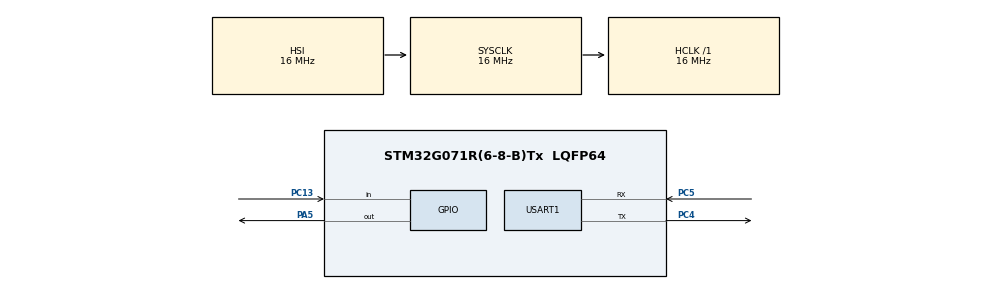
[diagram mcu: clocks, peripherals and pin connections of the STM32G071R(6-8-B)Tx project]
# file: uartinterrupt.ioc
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Mcu.Family=STM32G0
Mcu.Name=STM32G071R(6-8-B)Tx
Mcu.Package=LQFP64
NVIC.USART1_IRQn=true\:0\:0\:false\:false\:true\:true\:true
PA5.GPIO_Speed=GPIO_SPEED_FREQ_MEDIUM
PA5.Signal=GPIO_Output
PC13.Signal=GPIO_Input
PC4.Mode=Asynchronous
PC4.Signal=USART1_TX
PC5.Mode=Asynchronous
PC5.Signal=USART1_RX
ProjectManager.HeapSize=0x200
ProjectManager.StackSize=0x400
ProjectManager.TargetToolchain=MDK-ARM V5.27
RCC.AHBFreq_Value=16000000
RCC.CortexFreq_Value=16000000
RCC.EXTERNAL_CLOCK_VALUE=48000
RCC.HCLKFreq_Value=16000000
RCC.HSE_VALUE=8000000
RCC.HSI_VALUE=16000000
RCC.LSE_VALUE=32768
RCC.SYSCLKFreq_VALUE=16000000
RCC.VCOOutputFreq_Value=128000000
USART1.VirtualMode-Asynchronous=VM_ASYNC
VP_SYS_VS_DBSignals.Mode=DisableDeadBatterySignals
board=custom

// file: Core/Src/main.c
/* USER CODE BEGIN Header */
/**
  ******************************************************************************
  * @file           : main.c
  * @brief          : Main program body
  ******************************************************************************
  * @attention
  *
  * <h2><center>&copy; Copyright (c) 2021 STMicroelectronics.
  * All rights reserved.</center></h2>
  *
  * This software component is licensed by ST under BSD 3-Clause license,
  * the "License"; You may not use this file except in compliance with the
  * License. You may obtain a copy of the License at:
  *                        opensource.org/licenses/BSD-3-Clause
  *
  ******************************************************************************
  */
/* USER CODE END Header */
#include "main.h"
#define transmitter_board

UART_HandleTypeDef huart1;

/* USER CODE BEGIN PV */
__IO ITStatus uartready=RESET;
uint8_t TxMessage[1]={1};
uint8_t RxMessage[1];

uint8_t i=1;
/* USER CODE END PV */

void SystemClock_Config(void);
static void MX_GPIO_Init(void);
static void MX_USART1_UART_Init(void);

int main(void)
{

  /* MCU Configuration--------------------------------------------------------*/

  /* Reset of all peripherals, Initializes the Flash interface and the Systick. */
  HAL_Init();

  /* Configure the system clock */
  SystemClock_Config();

  /* Initialize all configured peripherals */
  MX_GPIO_Init();
  MX_USART1_UART_Init();
  /* USER CODE BEGIN 2 */

#ifdef transmitter_board
while(HAL_GPIO_ReadPin(GPIOC,GPIO_PIN_13)==1){

HAL_GPIO_TogglePin(GPIOA,GPIO_PIN_5);
	HAL_Delay(500);

}

if(HAL_UART_Transmit_IT(&huart1,(uint8_t *)TxMessage,1)!=HAL_OK)
	{
			Error_Handler();
	}
	while(uartready!=SET)
		{

		}

		uartready=RESET;
if(HAL_UART_Receive_IT(&huart1,(uint8_t *)RxMessage,1)!=HAL_OK)
	{
			Error_Handler();
	}

#else

   if(HAL_UART_Receive_IT(&huart1,(uint8_t *)RxMessage,1)!=HAL_OK){

			Error_Handler();

			}
	while(uartready!=SET)
		{

		}	uartready=RESET;
	if(HAL_UART_Transmit_IT(&huart1,(uint8_t *)TxMessage,1)!=HAL_OK)
			{

			Error_Handler();

			}

#endif

 while(uartready!=SET){

 }

 uartready=RESET;

 HAL_GPIO_WritePin(GPIOA,GPIO_PIN_5,GPIO_PIN_SET);
 while (1)
  {

			}
		/*TxMessage[0]=1;

	HAL_UART_Transmit_IT(&huart1,TxMessage,1);*/

    /* USER CODE END WHILE */

  }

void SystemClock_Config(void)
{
  RCC_OscInitTypeDef RCC_OscInitStruct = {0};
  RCC_ClkInitTypeDef RCC_ClkInitStruct = {0};
  RCC_PeriphCLKInitTypeDef PeriphClkInit = {0};

  /** Configure the main internal regulator output voltage
  */
  HAL_PWREx_ControlVoltageScaling(PWR_REGULATOR_VOLTAGE_SCALE1);
  /** Initializes the RCC Oscillators according to the specified parameters
  * in the RCC_OscInitTypeDef structure.
  */
  RCC_OscInitStruct.OscillatorType = RCC_OSCILLATORTYPE_HSI;
  RCC_OscInitStruct.HSIState = RCC_HSI_ON;
  RCC_OscInitStruct.HSIDiv = RCC_HSI_DIV1;
  RCC_OscInitStruct.HSICalibrationValue = RCC_HSICALIBRATION_DEFAULT;
  RCC_OscInitStruct.PLL.PLLState = RCC_PLL_NONE;
  if (HAL_RCC_OscConfig(&RCC_OscInitStruct) != HAL_OK)
  {
    Error_Handler();
  }
  /** Initializes the CPU, AHB and APB buses clocks
  */
  RCC_ClkInitStruct.ClockType = RCC_CLOCKTYPE_HCLK|RCC_CLOCKTYPE_SYSCLK
                              |RCC_CLOCKTYPE_PCLK1;
  RCC_ClkInitStruct.SYSCLKSource = RCC_SYSCLKSOURCE_HSI;
  RCC_ClkInitStruct.AHBCLKDivider = RCC_SYSCLK_DIV1;
  RCC_ClkInitStruct.APB1CLKDivider = RCC_HCLK_DIV1;

  if (HAL_RCC_ClockConfig(&RCC_ClkInitStruct, FLASH_LATENCY_0) != HAL_OK)
  {
    Error_Handler();
  }
  /** Initializes the peripherals clocks
  */
  PeriphClkInit.PeriphClockSelection = RCC_PERIPHCLK_USART1;
  PeriphClkInit.Usart1ClockSelection = RCC_USART1CLKSOURCE_PCLK1;
  if (HAL_RCCEx_PeriphCLKConfig(&PeriphClkInit) != HAL_OK)
  {
    Error_Handler();
  }
}

static void MX_USART1_UART_Init(void)
{

  huart1.Instance = USART1;
  huart1.Init.BaudRate = 115200;
  huart1.Init.WordLength = UART_WORDLENGTH_8B;
  huart1.Init.StopBits = UART_STOPBITS_1;
  huart1.Init.Parity = UART_PARITY_NONE;
  huart1.Init.Mode = UART_MODE_TX_RX;
  huart1.Init.HwFlowCtl = UART_HWCONTROL_NONE;
  huart1.Init.OverSampling = UART_OVERSAMPLING_16;
  huart1.Init.OneBitSampling = UART_ONE_BIT_SAMPLE_DISABLE;
  huart1.Init.ClockPrescaler = UART_PRESCALER_DIV1;
  huart1.AdvancedInit.AdvFeatureInit = UART_ADVFEATURE_NO_INIT;
  if (HAL_UART_Init(&huart1) != HAL_OK)
  {
    Error_Handler();
  }
  if (HAL_UARTEx_SetTxFifoThreshold(&huart1, UART_TXFIFO_THRESHOLD_1_8) != HAL_OK)
  {
    Error_Handler();
  }
  if (HAL_UARTEx_SetRxFifoThreshold(&huart1, UART_RXFIFO_THRESHOLD_1_8) != HAL_OK)
  {
    Error_Handler();
  }
  if (HAL_UARTEx_DisableFifoMode(&huart1) != HAL_OK)
  {
    Error_Handler();
  }

}

static void MX_GPIO_Init(void)
{
  GPIO_InitTypeDef GPIO_InitStruct = {0};

  /* GPIO Ports Clock Enable */
  __HAL_RCC_GPIOC_CLK_ENABLE();
  __HAL_RCC_GPIOA_CLK_ENABLE();

  /*Configure GPIO pin Output Level */
  HAL_GPIO_WritePin(GPIOA, GPIO_PIN_5, GPIO_PIN_RESET);

  /*Configure GPIO pin : PC13 */
  GPIO_InitStruct.Pin = GPIO_PIN_13;
  GPIO_InitStruct.Mode = GPIO_MODE_INPUT;
  GPIO_InitStruct.Pull = GPIO_NOPULL;
  HAL_GPIO_Init(GPIOC, &GPIO_InitStruct);

  /*Configure GPIO pin : PA5 */
  GPIO_InitStruct.Pin = GPIO_PIN_5;
  GPIO_InitStruct.Mode = GPIO_MODE_OUTPUT_PP;
  GPIO_InitStruct.Pull = GPIO_NOPULL;
  GPIO_InitStruct.Speed = GPIO_SPEED_FREQ_MEDIUM;
  HAL_GPIO_Init(GPIOA, &GPIO_InitStruct);

}
void HAL_UART_TxCpltCallback(UART_HandleTypeDef *huart){

uartready=SET;

}
void HAL_UART_RxCpltCallback(UART_HandleTypeDef *huart){

uartready=SET;

}

void Error_Handler(void)
{
  /* USER CODE BEGIN Error_Handler_Debug */
  /* User can add his own implementation to report the HAL error return state */
  __disable_irq();
  while (1)
  {
		HAL_GPIO_TogglePin(GPIOA,GPIO_PIN_5);
		HAL_Delay(500);
  }
  /* USER CODE END Error_Handler_Debug */
}

/************************ (C) COPYRIGHT STMicroelectronics *****END OF FILE****/
